VERSION ""

NS_ :

BS_:

BU_: U2C

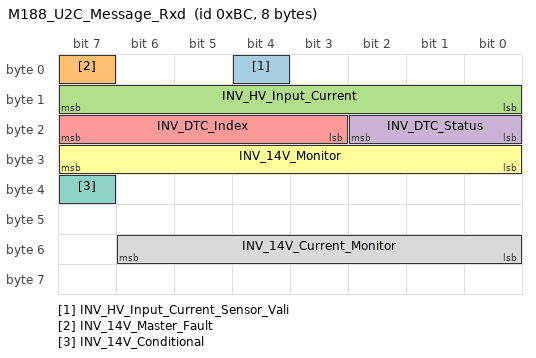
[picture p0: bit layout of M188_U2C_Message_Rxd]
BO_ 188 M188_U2C_Message_Rxd: 8 U2C
 SG_ INV_HV_Input_Current_Sensor_Vali : 4|1@1+ (1,0) [0|1] "" Vector__XXX
 SG_ INV_14V_Master_Fault : 7|1@1+ (1,0) [0|1] "" Vector__XXX
 SG_ INV_HV_Input_Current : 8|8@1+ (1,0) [0|255] "" Vector__XXX
 SG_ INV_DTC_Status : 16|3@1+ (1,0) [0|7] "" Vector__XXX
 SG_ INV_DTC_Index : 19|5@1+ (1,0) [0|31] "" Vector__XXX
 SG_ INV_14V_Monitor : 24|8@1+ (1,0) [0|255] "" Vector__XXX
 SG_ INV_14V_Conditional : 39|1@1+ (1,0) [0|1] "" Vector__XXX
 SG_ INV_14V_Current_Monitor : 48|7@1+ (1,0) [0|127] "" Vector__XXX

CM_ BU_ U2C "Delphi DC/DC Converter";
CM_ BO_ 188 "Response from Delphi DC/DC converter.";

BA_DEF_ SG_  "SystemSignalLongSymbol" STRING ;
BA_DEF_DEF_  "SystemSignalLongSymbol" "";

BA_ "SystemSignalLongSymbol" SG_ 188 INV_HV_Input_Current_Sensor_Vali "INV_HV_Input_Current_Sensor_Validity";
